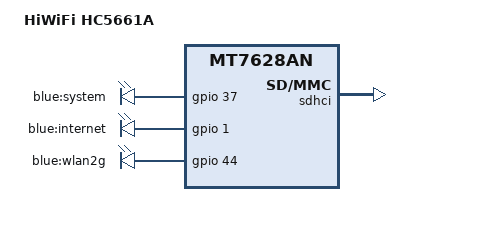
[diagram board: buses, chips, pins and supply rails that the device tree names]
#include "mt7628an_hiwifi_hc5x61a.dtsi"

/ {
	compatible = "hiwifi,hc5661a", "mediatek,mt7628an-soc";
	model = "HiWiFi HC5661A";

	leds {
		compatible = "gpio-leds";

		led_system: system {
			label = "blue:system";
			gpios = <&gpio 37 GPIO_ACTIVE_HIGH>;
		};

		internet {
			label = "blue:internet";
			gpios = <&gpio 1 GPIO_ACTIVE_HIGH>;
		};

		wlan2g {
			label = "blue:wlan2g";
			gpios = <&gpio 44 GPIO_ACTIVE_HIGH>;
			linux,default-trigger = "phy0tpt";
		};
	};
};
&pinctrl {
	sdxc_router_pins: sdxc_router_mode {
		gpio {
			ralink,group = "i2s", "sdmode", "uart1", "gpio";
			ralink,function = "gpio";
		};

		esdmode {
			ralink,group = "esdmode";
			ralink,function = "sdxc";
		};
	};

	state_default: pinctrl0 {
		gpio {
			ralink,group = "i2c", "refclk", "wdt", "wled_an";
			ralink,function = "gpio";
		};
	};
};

&sdhci {
	status = "okay";
	pinctrl-0 = <&sdxc_router_pins>;
};


&ehci {
	status = "disabled";
};

&ohci {
	status = "disabled";
};
